# DEBUGSS_WRAP_ROM_TABLE_1_0_000720000000h register map
Vendor: Texas Instruments
Peripheral module from a debugger description file (folder AM275x).
Registers are 32-bit, read-only, reset values left out (the file's numbers can be read two ways) unless marked. A register's access mark holds for its fields unless they carry their own. Offsets are as the file gives them; lines under a group give offsets from that group; [hi:lo] are bit positions; {n}, {i} and the like mark numbered series; 'fields as' and 'values as' point back to an identical list; <NAME> marks a mode.

## rom_table_1_0
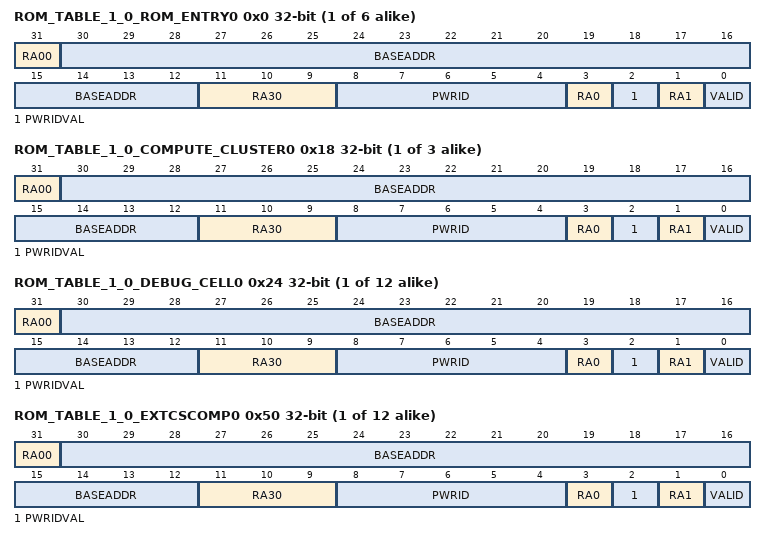
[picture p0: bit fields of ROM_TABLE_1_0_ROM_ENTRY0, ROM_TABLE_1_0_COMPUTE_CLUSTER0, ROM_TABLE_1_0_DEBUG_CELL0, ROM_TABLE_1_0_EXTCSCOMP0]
{0x0+4i} ROM_TABLE_1_0_ROM_ENTRY{i} (i=0..5)
  [31] RA00 — always read as 0
  [30:12] BASEADDR — Component base address
  [11:9] RA30 — always read as 0
  [8:4] PWRID — always read as 0
  [3] RA0 — always read as 0
  [2] PWRIDVAL — power id valid
  [1] RA1 — always read as 1
  [0] VALID — Component present,1, or not present,0, status bit
{0x18+4i} ROM_TABLE_1_0_COMPUTE_CLUSTER{i} (i=0..2)
  fields as ROM_TABLE_1_0_ROM_ENTRY0
{0x24+4i} ROM_TABLE_1_0_DEBUG_CELL{i} (i=0..11)
  fields as ROM_TABLE_1_0_ROM_ENTRY0
{0x50+4i} ROM_TABLE_1_0_EXTCSCOMP{i} (i=0..11)
  fields as ROM_TABLE_1_0_ROM_ENTRY0
